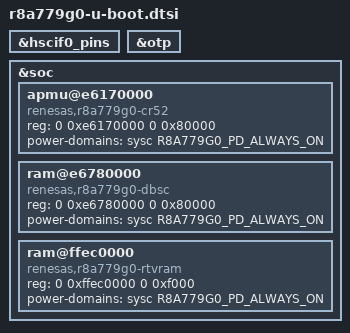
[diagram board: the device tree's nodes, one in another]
// SPDX-License-Identifier: GPL-2.0
/*
 * Device Tree Source extras for U-Boot on R-Car R8A779G0 SoC
 *
 * Copyright (C) 2021 Renesas Electronics Corp.
 */

&hscif0_pins {
	bootph-all;
};

&otp {
	bootph-all;
};

&soc {
	apmu@e6170000 {	/* Remoteproc */
		compatible = "renesas,r8a779g0-cr52";
		reg = <0 0xe6170000 0 0x80000>;
		power-domains = <&sysc R8A779G0_PD_ALWAYS_ON>;
		status = "okay";
	};

	ram@e6780000 {	/* DBSC5 */
		compatible = "renesas,r8a779g0-dbsc";
		reg = <0 0xe6780000 0 0x80000>;
		power-domains = <&sysc R8A779G0_PD_ALWAYS_ON>;
		status = "okay";
		bootph-all;
	};

	ram@ffec0000 {	/* RT-VRAM */
		compatible = "renesas,r8a779g0-rtvram";
		reg = <0 0xffec0000 0 0xf000>;
		power-domains = <&sysc R8A779G0_PD_ALWAYS_ON>;
		status = "okay";
		bootph-all;
	};
};
